# VPAC0_COMMON_0_PAR_VPAC_VISS0_S_VBUSP_VPAC_VISS_LSE_CFG_VP register map
Vendor: Texas Instruments
Peripheral module from a debugger description file (folder J7_AHP).
Registers are 32-bit, access per field, reset values left out (the file's numbers can be read two ways) unless marked. A register's access mark holds for its fields unless they carry their own. Offsets are as the file gives them; lines under a group give offsets from that group; [hi:lo] are bit positions; {n}, {i} and the like mark numbered series; 'fields as' and 'values as' point back to an identical list; <NAME> marks a mode.

## VPAC0_COMMON_0_PAR_VPAC_VISS0_S_VBUSP_VPAC_VISS_LSE_CFG_VP
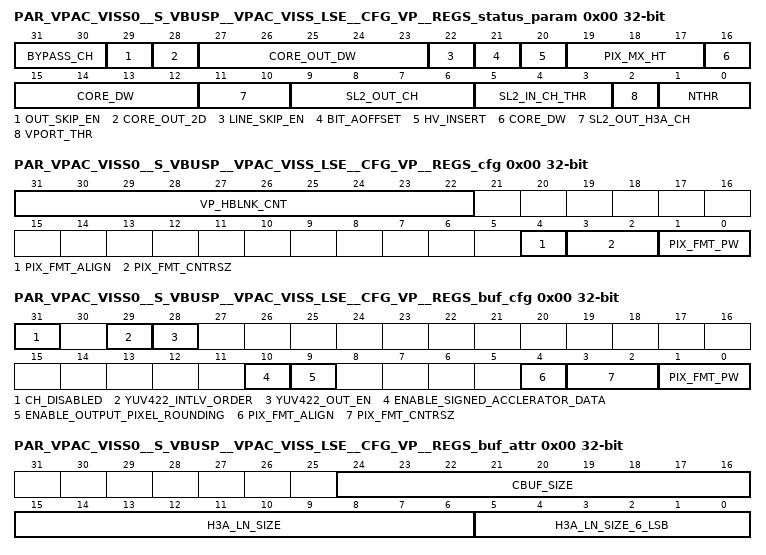
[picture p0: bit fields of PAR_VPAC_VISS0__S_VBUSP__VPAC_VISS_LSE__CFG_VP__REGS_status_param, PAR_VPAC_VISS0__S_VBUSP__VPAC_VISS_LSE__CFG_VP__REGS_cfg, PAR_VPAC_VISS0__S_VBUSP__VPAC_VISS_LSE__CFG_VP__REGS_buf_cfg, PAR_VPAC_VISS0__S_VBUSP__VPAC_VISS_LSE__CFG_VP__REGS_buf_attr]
0x00 PAR_VPAC_VISS0__S_VBUSP__VPAC_VISS_LSE__CFG_VP__REGS_status_param ro
  [31:30] BYPASS_CH — Number of available input channel selection for loopback mode
  [29] OUT_SKIP_EN — Output Auto-Skip Enable
  [28] CORE_OUT_2D — 1D or 2D output addressing mode(2D if 1)
  [27:23] CORE_OUT_DW — Core Output Channel Data Width
  [22] LINE_SKIP_EN — Source Line Inc by 2 Supported (if 1)
  [21] BIT_AOFFSET — Source nibble offset address Supported (if 1)
  [20] HV_INSERT — H/VBLANK Insertion Supported (if 1)
  [19:17] PIX_MX_HT — Core_Input Pixel Matrix Height
  [16:12] CORE_DW — Core Input Data Bus Width
  [11:10] SL2_OUT_H3A_CH — Number of SL2 H3A Output Channels
  [9:6] SL2_OUT_CH — Number of SL2 Output Channels
  [5:3] SL2_IN_CH_THR — Number of Input Channels per thread
  [2] VPORT_THR — Number of VPORT input enabled
  [1:0] NTHR — Number of threads supported
0x00 PAR_VPAC_VISS0__S_VBUSP__VPAC_VISS_LSE__CFG_VP__REGS_cfg rw
  [31:22] VP_HBLNK_CNT — Number of HBlank Pixels to insert between active lines for internal vport interface to core. (Max=1023) Must be set to 0 if hblank insertion is not needed by HWA_CORE Else must be at least 2 (2 or more hblank cycles)
  [4] PIX_FMT_ALIGN — Input Pixel Container Alignment 0: LSB-aligned 1: MSB-aligned
  [3:2] PIX_FMT_CNTRSZ — Input Pixel Container Size Sel 0: 8-bit 1: 12-bit 2: 16-bit 3: reserved Input pixel container size must be same or larger than input pixel width.
  [1:0] PIX_FMT_PW — Input Pixel Width Sel 0: 8-bit 1: 12-bit 2: 14-bit 3: 16-bit The width defines the bit-depth of the pixel data to be extracted from the pixel container.
0x00 PAR_VPAC_VISS0__S_VBUSP__VPAC_VISS_LSE__CFG_VP__REGS_buf_cfg
  [31] CH_DISABLED ro — Channel Disable Status (read-only) 0: (Default) Chanel is enabled for Y, UV or YUV422 data transfer to SL2 memory. All configurations associated with this DST_BUF[a] are valid. 1: Channel is disabled for SL2 data transfer (because the channel logic is used internally for YUV data interleaving). All configuration associated with this DST_BUF[a] are ignored.
  [29] YUV422_INTLV_ORDER rw — YUV422 Interleaving Order Selection 0: UYVY 1: YUYV Only Applicable if this output channel is YUV422 output capable LUMA channel. Otherwise, setting has no effect.
  [28] YUV422_OUT_EN rw — YUV422 Interleaved Output Merge Enable 0: Disable 1: Enable When enabled, this channel interleaves data from the associated chroma data output channel to output YUV422 interleaved data to the SL2 memory. Only Applicable if this output channel is YUV422 output capable LUMA channel. Otherwise, setting has no effect.
  [10] ENABLE_SIGNED_ACCLERATOR_DATA rw — Specify the acclerator data to be signed or unsigned 0: Unsigned data (By default) 1: Signed Data
  [9] ENABLE_OUTPUT_PIXEL_ROUNDING rw — enable acclerator pixel output rounding 0: Disable rounding logic 1: Enable rounding logic
  [4] PIX_FMT_ALIGN rw — Output Pixel Container Alignment 0: LSB-aligned 1: MSB-aligned
  [3:2] PIX_FMT_CNTRSZ rw — Output Pixel Container Size Sel 0: 8-bit 1: 12-bit 2: 16-bit 3: reserved Output pixel container size must be same or larger than output pixel width. If yuv422_out_en is set, pix_fmt_cntrsz must be 0.
  [1:0] PIX_FMT_PW rw — Output Pixel Width Sel 0: 8-bit 1: 12-bit 2: reserved 3: 16-bit The width defines the bit-depth of the pixel data to be stored in the pixel container.
0x00 PAR_VPAC_VISS0__S_VBUSP__VPAC_VISS_LSE__CFG_VP__REGS_buf_attr
  [24:16] CBUF_SIZE rw — SL2 Circular Buffer Size (number of H3A Line buffers)
  [15:6] H3A_LN_SIZE rw — H3A Output Done Line Size [15:0] Size of H3A output line size in bytes for HTS Done generation (64 byte multiple) This is equivalent to Buf_Stride.
  [5:0] H3A_LN_SIZE_6_LSB ro — H3A Output Done Line Size [5:0] - 6 LSB bits should always be 0. Writes have no effect. Always read as 0
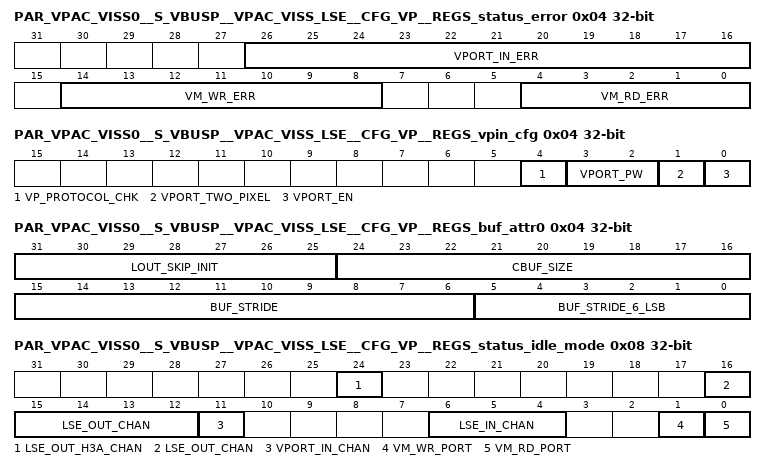
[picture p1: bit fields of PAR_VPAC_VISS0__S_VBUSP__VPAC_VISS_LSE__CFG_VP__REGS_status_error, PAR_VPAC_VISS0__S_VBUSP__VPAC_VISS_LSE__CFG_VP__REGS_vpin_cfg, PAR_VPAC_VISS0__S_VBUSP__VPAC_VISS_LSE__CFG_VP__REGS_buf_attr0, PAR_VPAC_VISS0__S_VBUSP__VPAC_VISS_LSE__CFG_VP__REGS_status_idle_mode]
0x04 PAR_VPAC_VISS0__S_VBUSP__VPAC_VISS_LSE__CFG_VP__REGS_status_error access not given
  [26:16] VPORT_IN_ERR — VPORT_CAL Input Error Status Protocol Errors [26] VS without HS [25] VE without HE [24] VS-VS (missing VE) Error [23] HS-HS (missing HE) Error [22] HE-HE (missing HS) Error [21] VE-VE (missing VS) Error Frame Size Errors [20] Frame Skipped during Error Handling [19] Long Frame detected [18] Short Frame detected [17] Long Line detected [16] Short Line Detected (access R/W1TC)
  [14:8] VM_WR_ERR — VBUSM I/F Last Write Error Status [14:11] Write Channel Number [10:8] VBUSM write error status (access R/W1TC)
  [4:0] VM_RD_ERR — VBUSM I/F Last Read Error Status [4:3] Read Channel Number [2:0] VBUSM read error status (access R/W1TC)
0x04 PAR_VPAC_VISS0__S_VBUSP__VPAC_VISS_LSE__CFG_VP__REGS_vpin_cfg rw
  [4] VP_PROTOCOL_CHK — Vport Input Data Protocol Check Enable 0: Disable 1: Enable
  [3:2] VPORT_PW — Vport Pixel Data Width Sel 0: 8-bit 1: 12-bit 2: 14-bit 3: 16-bit Vport Pixels are always LSB aligned in 16-bit halfword
  [1] VPORT_TWO_PIXEL — Number of pixels per vport cycles 0: 1 pixels 1: 2 pixels
  [0] VPORT_EN — vport_en 0: Disable 1: Enable When Enabled, external VPORT input data is selected instead of SRC channel 0 of this thread
0x04 PAR_VPAC_VISS0__S_VBUSP__VPAC_VISS_LSE__CFG_VP__REGS_buf_attr0
  [31:25] LOUT_SKIP_INIT rw — Line Out Initial Skip Count - The number of initial HTS tstart/tdone cycles with no output from the core on this output channel. The LSE will auto-generate the channel done status during these cycles.
  [24:16] CBUF_SIZE rw — SL2 Circular Buffer Size (number of line buffers)
  [15:6] BUF_STRIDE rw — Buffer Stride Size [15:6] (64 byte multiple) stride size
  [5:0] BUF_STRIDE_6_LSB ro — Buffer Stride Size [5:0] - 6 LSB bits of buffer stride size should always be 0. Writes have no effect. Always read as 0
0x08 PAR_VPAC_VISS0__S_VBUSP__VPAC_VISS_LSE__CFG_VP__REGS_status_idle_mode ro
  [24] LSE_OUT_H3A_CHAN — Output H3A Channel Status
  [16:12] LSE_OUT_CHAN — Output Channel[4:0] Status
  [11] VPORT_IN_CHAN — CAL I/F Vport Input Cahnnel Status
  [6:4] LSE_IN_CHAN — Input Channel[2:0] Status
  [1] VM_WR_PORT — SL2 vbusm I/F Write Port Status
  [0] VM_RD_PORT — SL2 vbusm I/F Read Port Status
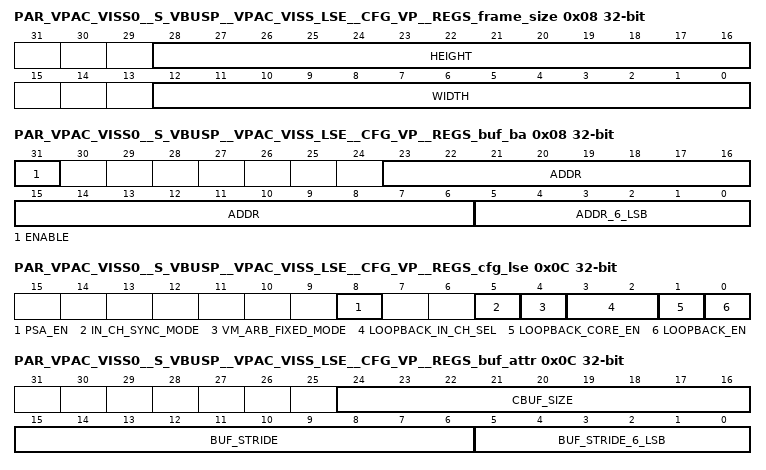
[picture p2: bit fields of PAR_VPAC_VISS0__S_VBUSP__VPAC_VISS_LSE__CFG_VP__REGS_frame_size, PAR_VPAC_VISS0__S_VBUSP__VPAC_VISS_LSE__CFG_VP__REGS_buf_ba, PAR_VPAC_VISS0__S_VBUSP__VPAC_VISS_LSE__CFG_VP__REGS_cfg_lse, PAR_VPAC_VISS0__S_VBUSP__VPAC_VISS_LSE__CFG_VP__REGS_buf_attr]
0x08 PAR_VPAC_VISS0__S_VBUSP__VPAC_VISS_LSE__CFG_VP__REGS_frame_size rw
  [28:16] HEIGHT — SL2 - Source Buffer Height (number of lines)
  [12:0] WIDTH — SL2 - Source Buffer Width (number of pixels)
0x08 PAR_VPAC_VISS0__S_VBUSP__VPAC_VISS_LSE__CFG_VP__REGS_buf_ba
  [31] ENABLE rw — Output H3A Buffer Enable 0: Disable 1: Enable
  [23:6] ADDR rw — Base Address[23:6] - (64 Byte aligned) byte address
  [5:0] ADDR_6_LSB ro — Base Address[5:0] - 6 LSB bits of address should always be 0. Writes have no effect. Always read as 0
0x0C PAR_VPAC_VISS0__S_VBUSP__VPAC_VISS_LSE__CFG_VP__REGS_cfg_lse rw
  [8] PSA_EN — Test mode Output Channel Signature Generation Enable 0: Disable (default) 1: Enable When enabled, LSE generates a unique CRC signature for each output channel's frame data at frame completion.
  [5] IN_CH_SYNC_MODE — Input Channel Transfer Sync Mode (applicable only for VISS) 0: Line Mode 1: Frame Mode (default) When set to 0 (Line Mode), LSE waits for a HTS_TSTART on every line reads from SL2. When set to 1 (Frame Mode), LSE waits for the first HTS_TSTART after HTS_INIT to start reading the first line of the frame. Afterward, it continues to read frame data (next lines) from the SL2 without waiting for HTS_TSTART as long as LSE is able to send the data to the core logic without being stalled.
  [4] VM_ARB_FIXED_MODE — VBUSM Arbitration Fixed Mode select 0: Round-Robin Arbitration (default) 1: Fixed-mode Arbitration
  [3:2] LOOPBACK_IN_CH_SEL — Loopback Input Channel Select (applicable only for VISS) 0: Ch0/CAL_Vport_In 1: Ch1 2: Ch2
  [1] LOOPBACK_CORE_EN — Functional path (data to HWA core) enable during loopback mode 0: Disable 1: Enable When enabled, the loopback-enabled input channel is used also for CORE data input. Otherwise, it is strictly used for the loopback path.
  [0] LOOPBACK_EN — LSE loopback mode enable 0: Disable 1: Enable When enabled, selected input channel data is looped back out to the last (#4) output channel.
0x0C PAR_VPAC_VISS0__S_VBUSP__VPAC_VISS_LSE__CFG_VP__REGS_buf_attr
  [24:16] CBUF_SIZE rw — SL2 Circular Buffer Size (number of line buffers)
  [15:6] BUF_STRIDE rw — Buffer Stride Size [15:6] (64 byte multiple) stride size
  [5:0] BUF_STRIDE_6_LSB ro — Buffer Stride Size [5:0] - 6 LSB bits of buffer stride size should always be 0. Writes have no effect. Always read as 0
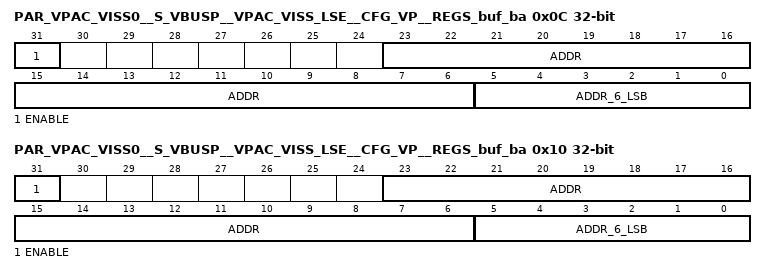
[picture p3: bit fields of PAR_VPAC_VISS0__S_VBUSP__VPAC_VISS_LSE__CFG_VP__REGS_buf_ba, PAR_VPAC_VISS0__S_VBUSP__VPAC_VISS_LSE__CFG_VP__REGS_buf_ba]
0x0C PAR_VPAC_VISS0__S_VBUSP__VPAC_VISS_LSE__CFG_VP__REGS_buf_ba
  [31] ENABLE rw — Output Channel Enable 0: Disable 1: Enable
  [23:6] ADDR rw — Base Address[23:6] - (64 Byte aligned) byte address
  [5:0] ADDR_6_LSB ro — Base Address[5:0] - 6 LSB bits of address should always be 0. Writes have no effect. Always read as 0
0x10 PAR_VPAC_VISS0__S_VBUSP__VPAC_VISS_LSE__CFG_VP__REGS_buf_ba
  [31] ENABLE rw — Input Buffer Enable 0: Disable 1: Enable When the processing thread is enabled, at least one of the input buffer must be enabled
  [23:6] ADDR rw — Base Address[23:6] - (64 Byte aligned) byte address
  [5:0] ADDR_6_LSB ro — Base Address[5:0] - 6 LSB bits of address should always be 0. Writes have no effect. Always read as 0
0x13C PAR_VPAC_VISS0__S_VBUSP__VPAC_VISS_LSE__CFG_VP__REGS_dst_common_cfg rw
  [5:0] ROUNDING_OFFSET — output channel rounding offset value. Default value to be considered 6'h08
0x140 PAR_VPAC_VISS0__S_VBUSP__VPAC_VISS_LSE__CFG_VP__REGS_psa_signature ro
  [31:0] VALUE — 32-bit CRC signature value
0x1E0 PAR_VPAC_VISS0__S_VBUSP__VPAC_VISS_LSE__CFG_VP__REGS_dbg ro
  [31:0] STATUS — Debug status
